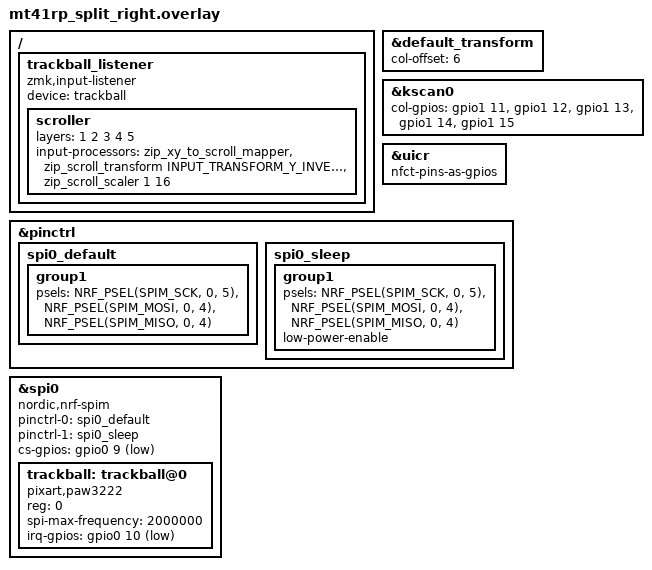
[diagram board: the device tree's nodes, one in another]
#include "mt41rp_split.dtsi"
#include <zephyr/dt-bindings/input/input-event-codes.h>
#include <dt-bindings/zmk/input_transform.h>
#include <input/processors.dtsi>

&default_transform {
    col-offset = <6>;
};

&kscan0 {
    col-gpios
        = <&gpio1 11 GPIO_ACTIVE_HIGH>  // D6  col1（最下段は親指）
        , <&gpio1 12 GPIO_ACTIVE_HIGH>  // D7  col2
        , <&gpio1 13 GPIO_ACTIVE_HIGH>  // D8  col3
        , <&gpio1 14 GPIO_ACTIVE_HIGH>  // D9  col4
        , <&gpio1 15 GPIO_ACTIVE_HIGH>  // D10 col5
        ;
};

// トラックボールの cs / mot が NFC1 / NFC2（P0.09 / P0.10）
&uicr {
    nfct-pins-as-gpios;
};

/ {
    trackball_listener {
        compatible = "zmk,input-listener";
        device = <&trackball>;
        scroller {
            layers = <1 2 3 4 5>;
            input-processors = <
                &zip_xy_to_scroll_mapper                       // XY移動でスクロール
                &zip_scroll_transform INPUT_TRANSFORM_Y_INVERT // スクロールのY軸を反転
                &zip_scroll_scaler 1 16                        // スクロール感度調整
            >;
        };
    };
};

&pinctrl {
    spi0_default: spi0_default {
        group1 {
            psels = <NRF_PSEL(SPIM_SCK, 0, 5)>,    // D5 sclk
                <NRF_PSEL(SPIM_MOSI, 0, 4)>,       // D4 sdio（3線式なので MOSI/MISO 共通）
                <NRF_PSEL(SPIM_MISO, 0, 4)>;
        };
    };

    spi0_sleep: spi0_sleep {
        group1 {
            psels = <NRF_PSEL(SPIM_SCK, 0, 5)>,
                <NRF_PSEL(SPIM_MOSI, 0, 4)>,
                <NRF_PSEL(SPIM_MISO, 0, 4)>;
            low-power-enable;
        };
    };
};

&spi0 {
    status = "okay";
    compatible = "nordic,nrf-spim";
    pinctrl-0 = <&spi0_default>;
    pinctrl-1 = <&spi0_sleep>;
    pinctrl-names = "default", "sleep";
    cs-gpios = <&gpio0 9 GPIO_ACTIVE_LOW>;  // NFC1 cs

    trackball: trackball@0 {
        status = "okay";
        compatible = "pixart,paw3222";
        reg = <0>;
        spi-max-frequency = <2000000>;
        irq-gpios = <&gpio0 10 (GPIO_ACTIVE_LOW | GPIO_PULL_UP)>;  // NFC2 mot

        // センサーの向き: ortho42tb（invert-x / invert-y）から 180° 回転させたもの。
        // 180° 回転は X・Y の両方の反転なので、どちらの invert も付けない。
    };
};
